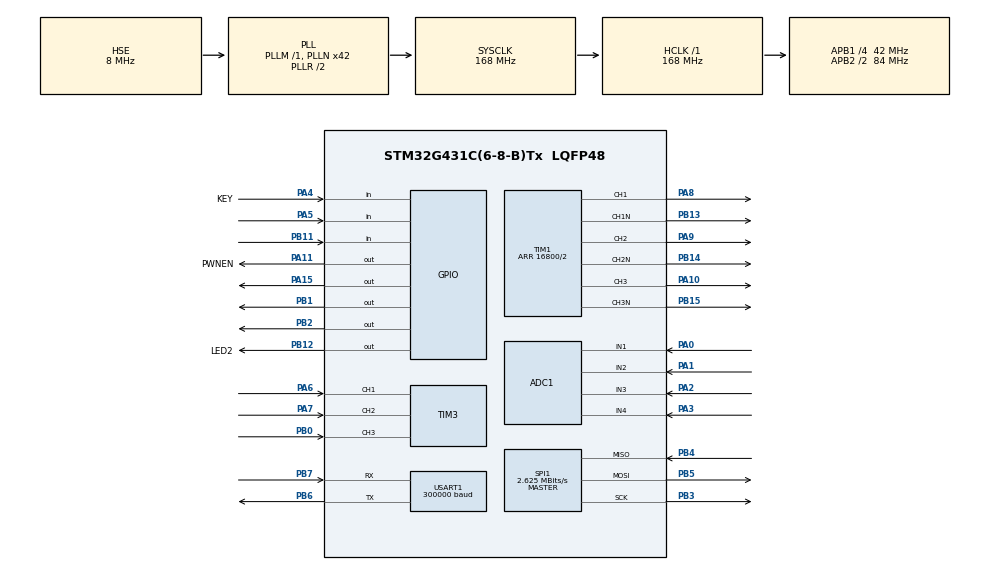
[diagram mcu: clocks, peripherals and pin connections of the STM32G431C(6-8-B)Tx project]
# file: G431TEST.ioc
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ADC1.Channel-10\#ChannelRegularConversion=ADC_CHANNEL_4
ADC1.Channel-7\#ChannelRegularConversion=ADC_CHANNEL_1
ADC1.Channel-8\#ChannelRegularConversion=ADC_CHANNEL_2
ADC1.Channel-9\#ChannelRegularConversion=ADC_CHANNEL_3
ADC1.ClockPrescaler=ADC_CLOCK_SYNC_PCLK_DIV4
ADC1.ContinuousConvMode=ENABLE
ADC1.DMAContinuousRequests=ENABLE
ADC1.EOCSelection=ADC_EOC_SINGLE_CONV
ADC1.EnableInjectedConversion=ENABLE
ADC1.EnableInjectedOversampling=DISABLE
ADC1.EnableRegularConversion=ENABLE
ADC1.ExternalTrigInjecConv=ADC_EXTERNALTRIGINJEC_T1_TRGO
ADC1.ExternalTrigInjecConvEdge=ADC_EXTERNALTRIGINJECCONV_EDGE_RISING
ADC1.InjNumberOfConversion=4
ADC1.InjectedChannel-1\#ChannelInjectedConversion=ADC_CHANNEL_1
ADC1.InjectedChannel-2\#ChannelInjectedConversion=ADC_CHANNEL_2
ADC1.InjectedChannel-5\#ChannelInjectedConversion=ADC_CHANNEL_3
ADC1.InjectedChannel-6\#ChannelInjectedConversion=ADC_CHANNEL_4
ADC1.InjectedConvMode=None
ADC1.InjectedOffsetNumber-1\#ChannelInjectedConversion=ADC_OFFSET_NONE
ADC1.InjectedOffsetNumber-2\#ChannelInjectedConversion=ADC_OFFSET_NONE
ADC1.InjectedOffsetNumber-5\#ChannelInjectedConversion=ADC_OFFSET_NONE
ADC1.InjectedOffsetNumber-6\#ChannelInjectedConversion=ADC_OFFSET_NONE
ADC1.InjectedRank-1\#ChannelInjectedConversion=1
ADC1.InjectedRank-2\#ChannelInjectedConversion=2
ADC1.InjectedRank-5\#ChannelInjectedConversion=3
ADC1.InjectedRank-6\#ChannelInjectedConversion=4
ADC1.InjectedSamplingTime-1\#ChannelInjectedConversion=ADC_SAMPLETIME_12CYCLES_5
ADC1.InjectedSamplingTime-2\#ChannelInjectedConversion=ADC_SAMPLETIME_12CYCLES_5
ADC1.InjectedSamplingTime-5\#ChannelInjectedConversion=ADC_SAMPLETIME_12CYCLES_5
ADC1.InjectedSamplingTime-6\#ChannelInjectedConversion=ADC_SAMPLETIME_12CYCLES_5
ADC1.NbrOfConversion=4
ADC1.NbrOfConversionFlag=1
ADC1.OffsetNumber-10\#ChannelRegularConversion=ADC_OFFSET_NONE
ADC1.OffsetNumber-7\#ChannelRegularConversion=ADC_OFFSET_NONE
ADC1.OffsetNumber-8\#ChannelRegularConversion=ADC_OFFSET_NONE
ADC1.OffsetNumber-9\#ChannelRegularConversion=ADC_OFFSET_NONE
ADC1.Rank-10\#ChannelRegularConversion=4
ADC1.Rank-7\#ChannelRegularConversion=1
ADC1.Rank-8\#ChannelRegularConversion=2
ADC1.Rank-9\#ChannelRegularConversion=3
ADC1.SamplingTime-10\#ChannelRegularConversion=ADC_SAMPLETIME_12CYCLES_5
ADC1.SamplingTime-7\#ChannelRegularConversion=ADC_SAMPLETIME_12CYCLES_5
ADC1.SamplingTime-8\#ChannelRegularConversion=ADC_SAMPLETIME_12CYCLES_5
ADC1.SamplingTime-9\#ChannelRegularConversion=ADC_SAMPLETIME_12CYCLES_5
ADC1.injectedQueueMode=DISABLE
ADC1.master=1
Dma.ADC1.2.Direction=DMA_PERIPH_TO_MEMORY
Dma.ADC1.2.EventEnable=DISABLE
Dma.ADC1.2.Instance=DMA1_Channel1
Dma.ADC1.2.MemDataAlignment=DMA_MDATAALIGN_HALFWORD
Dma.ADC1.2.MemInc=DMA_MINC_ENABLE
Dma.ADC1.2.Mode=DMA_CIRCULAR
Dma.ADC1.2.PeriphDataAlignment=DMA_PDATAALIGN_HALFWORD
Dma.ADC1.2.PeriphInc=DMA_PINC_DISABLE
Dma.ADC1.2.Polarity=HAL_DMAMUX_REQ_GEN_RISING
Dma.ADC1.2.Priority=DMA_PRIORITY_VERY_HIGH
Dma.ADC1.2.RequestNumber=1
Dma.ADC1.2.SignalID=NONE
Dma.ADC1.2.SyncEnable=DISABLE
Dma.ADC1.2.SyncPolarity=HAL_DMAMUX_SYNC_NO_EVENT
Dma.ADC1.2.SyncRequestNumber=1
Dma.ADC1.2.SyncSignalID=NONE
Dma.Request0=USART1_TX
Dma.Request1=USART1_RX
Dma.Request2=ADC1
Dma.USART1_RX.1.Direction=DMA_PERIPH_TO_MEMORY
Dma.USART1_RX.1.EventEnable=DISABLE
Dma.USART1_RX.1.Instance=DMA1_Channel4
Dma.USART1_RX.1.MemDataAlignment=DMA_MDATAALIGN_BYTE
Dma.USART1_RX.1.MemInc=DMA_MINC_ENABLE
Dma.USART1_RX.1.Mode=DMA_CIRCULAR
Dma.USART1_RX.1.PeriphDataAlignment=DMA_PDATAALIGN_BYTE
Dma.USART1_RX.1.PeriphInc=DMA_PINC_DISABLE
Dma.USART1_RX.1.Polarity=HAL_DMAMUX_REQ_GEN_RISING
Dma.USART1_RX.1.Priority=DMA_PRIORITY_VERY_HIGH
Dma.USART1_RX.1.RequestNumber=1
Dma.USART1_RX.1.SignalID=NONE
Dma.USART1_RX.1.SyncEnable=DISABLE
Dma.USART1_RX.1.SyncPolarity=HAL_DMAMUX_SYNC_NO_EVENT
Dma.USART1_RX.1.SyncRequestNumber=1
Dma.USART1_RX.1.SyncSignalID=NONE
Dma.USART1_TX.0.Direction=DMA_MEMORY_TO_PERIPH
Dma.USART1_TX.0.EventEnable=DISABLE
Dma.USART1_TX.0.Instance=DMA1_Channel3
Dma.USART1_TX.0.MemDataAlignment=DMA_MDATAALIGN_BYTE
Dma.USART1_TX.0.MemInc=DMA_MINC_ENABLE
Dma.USART1_TX.0.Mode=DMA_NORMAL
Dma.USART1_TX.0.PeriphDataAlignment=DMA_PDATAALIGN_BYTE
Dma.USART1_TX.0.PeriphInc=DMA_PINC_DISABLE
Dma.USART1_TX.0.Polarity=HAL_DMAMUX_REQ_GEN_RISING
Dma.USART1_TX.0.Priority=DMA_PRIORITY_HIGH
Dma.USART1_TX.0.RequestNumber=1
Dma.USART1_TX.0.SignalID=NONE
Dma.USART1_TX.0.SyncEnable=DISABLE
Dma.USART1_TX.0.SyncPolarity=HAL_DMAMUX_SYNC_NO_EVENT
Dma.USART1_TX.0.SyncRequestNumber=1
Dma.USART1_TX.0.SyncSignalID=NONE
Mcu.Family=STM32G4
Mcu.Name=STM32G431C(6-8-B)Tx
Mcu.Package=LQFP48
NVIC.ADC1_2_IRQn=true\:1\:0\:true\:false\:true\:true\:true
NVIC.DMA1_Channel3_IRQn=true\:0\:0\:true\:false\:true\:true\:true
NVIC.PriorityGroup=NVIC_PRIORITYGROUP_4
NVIC.TIM3_IRQn=true\:2\:0\:true\:false\:true\:true\:true
NVIC.USART1_IRQn=true\:2\:0\:true\:false\:true\:true\:true
PA0.Mode=IN1-Single-Ended
PA0.Signal=ADC1_IN1
PA1.Mode=IN2-Single-Ended
PA1.Signal=ADC1_IN2
PA10.Signal=S_TIM1_CH3
PA11.GPIO_Label=PWNEN
PA11.Signal=GPIO_Output
PA13.Mode=Serial_Wire
PA13.Signal=SYS_JTMS-SWDIO
PA14.Mode=Serial_Wire
PA14.Signal=SYS_JTCK-SWCLK
PA15.Signal=GPIO_Output
PA2.Mode=IN3-Single-Ended
PA2.Signal=ADC1_IN3
PA3.Mode=IN4-Single-Ended
PA3.Signal=ADC1_IN4
PA4.GPIO_Label=KEY
PA4.Signal=GPIO_Input
PA5.Signal=GPIO_Input
PA6.Signal=S_TIM3_CH1
PA7.Signal=S_TIM3_CH2
PA8.Signal=S_TIM1_CH1
PA9.Signal=S_TIM1_CH2
PB0.Signal=S_TIM3_CH3
PB1.Signal=GPIO_Output
PB11.Signal=GPIO_Input
PB12.GPIO_Label=LED2
PB12.PinState=GPIO_PIN_SET
PB12.Signal=GPIO_Output
PB13.Mode=PWM Generation1 CH1 CH1N
PB13.Signal=TIM1_CH1N
PB14.Mode=PWM Generation2 CH2 CH2N
PB14.Signal=TIM1_CH2N
PB15.Mode=PWM Generation3 CH3 CH3N
PB15.Signal=TIM1_CH3N
PB2.Signal=GPIO_Output
PB3.Mode=Full_Duplex_Master
PB3.Signal=SPI1_SCK
PB4.Mode=Full_Duplex_Master
PB4.Signal=SPI1_MISO
PB5.Mode=Full_Duplex_Master
PB5.Signal=SPI1_MOSI
PB6.Mode=Asynchronous
PB6.Signal=USART1_TX
PB7.Mode=Asynchronous
PB7.Signal=USART1_RX
PF0-OSC_IN.Mode=HSE-External-Oscillator
PF0-OSC_IN.Signal=RCC_OSC_IN
PF1-OSC_OUT.Mode=HSE-External-Oscillator
PF1-OSC_OUT.Signal=RCC_OSC_OUT
ProjectManager.HeapSize=0x200
ProjectManager.StackSize=0x400
ProjectManager.TargetToolchain=MDK-ARM V5.32
RCC.ADC12Freq_Value=168000000
RCC.AHBFreq_Value=168000000
RCC.APB1CLKDivider=RCC_HCLK_DIV4
RCC.APB1Freq_Value=42000000
RCC.APB1TimFreq_Value=84000000
RCC.APB2CLKDivider=RCC_HCLK_DIV2
RCC.APB2Freq_Value=84000000
RCC.APB2TimFreq_Value=168000000
RCC.CortexFreq_Value=168000000
RCC.EXTERNAL_CLOCK_VALUE=12288000
RCC.HCLKFreq_Value=168000000
RCC.HSE_VALUE=8000000
RCC.HSI48_VALUE=48000000
RCC.HSI_VALUE=16000000
RCC.LSE_VALUE=32768
RCC.PLLN=42
RCC.PLLSourceVirtual=RCC_PLLSOURCE_HSE
RCC.SYSCLKFreq_VALUE=168000000
RCC.SYSCLKSource=RCC_SYSCLKSOURCE_PLLCLK
RCC.USBFreq_Value=168000000
RCC.VCOOutputFreq_Value=336000000
SH.S_TIM1_CH1.0=TIM1_CH1,PWM Generation1 CH1 CH1N
SH.S_TIM1_CH2.0=TIM1_CH2,PWM Generation2 CH2 CH2N
SH.S_TIM1_CH3.0=TIM1_CH3,PWM Generation3 CH3 CH3N
SH.S_TIM3_CH1.0=TIM3_CH1,Encoder_Interface
SH.S_TIM3_CH2.0=TIM3_CH2,Encoder_Interface
SH.S_TIM3_CH3.0=TIM3_CH3,Input_Capture3_from_TI3
SPI1.BaudRatePrescaler=SPI_BAUDRATEPRESCALER_32
SPI1.CLKPhase=SPI_PHASE_2EDGE
SPI1.CalculateBaudRate=2.625 MBits/s
SPI1.DataSize=SPI_DATASIZE_16BIT
SPI1.Direction=SPI_DIRECTION_2LINES
SPI1.Mode=SPI_MODE_MASTER
SPI1.VirtualType=VM_MASTER
TIM1.AutoReloadPreload=TIM_AUTORELOAD_PRELOAD_ENABLE
TIM1.AutomaticOutput=TIM_AUTOMATICOUTPUT_ENABLE
TIM1.BreakState=TIM_BREAK_DISABLE
TIM1.Channel-PWM\ Generation1\ CH1\ CH1N=TIM_CHANNEL_1
TIM1.Channel-PWM\ Generation2\ CH2\ CH2N=TIM_CHANNEL_2
TIM1.Channel-PWM\ Generation3\ CH3\ CH3N=TIM_CHANNEL_3
TIM1.CounterMode=TIM_COUNTERMODE_CENTERALIGNED1
TIM1.DeadTime=100
TIM1.LockLevel=TIM_LOCKLEVEL_1
TIM1.OCMode_PWM-PWM\ Generation1\ CH1\ CH1N=TIM_OCMODE_PWM2
TIM1.OCMode_PWM-PWM\ Generation2\ CH2\ CH2N=TIM_OCMODE_PWM2
TIM1.OCMode_PWM-PWM\ Generation3\ CH3\ CH3N=TIM_OCMODE_PWM2
TIM1.OCPolarity_1=TIM_OCPOLARITY_HIGH
TIM1.OCPolarity_2=TIM_OCPOLARITY_HIGH
TIM1.OCPolarity_3=TIM_OCPOLARITY_HIGH
TIM1.OffStateIDLEMode=TIM_OSSI_ENABLE
TIM1.OffStateRunMode=TIM_OSSR_ENABLE
TIM1.PeriodNoDither=16800/2
TIM1.PulseNoDither_1=4200
TIM1.PulseNoDither_2=4200
TIM1.PulseNoDither_3=4200
TIM1.RepetitionCounter=1
TIM1.TIM_MasterOutputTrigger=TIM_TRGO_UPDATE
TIM3.Channel-Input_Capture3_from_TI3=TIM_CHANNEL_3
TIM3.ICPrescaler-Input_Capture3_from_TI3=TIM_ICPSC_DIV2
USART1.BaudRate=300000
USART1.VirtualMode-Asynchronous=VM_ASYNC
VP_SYS_VS_DBSignals.Mode=DisableDeadBatterySignals
VP_TIM1_VS_ClockSourceINT.Mode=Internal
board=custom

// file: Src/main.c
/* USER CODE BEGIN Header */
/**
  ******************************************************************************
  * @file           : main.c
  * @brief          : Main program body
  ******************************************************************************
  * @attention
  *
  * <h2><center>&copy; Copyright (c) 2023 STMicroelectronics.
  * All rights reserved.</center></h2>
  *
  * This software component is licensed by ST under BSD 3-Clause license,
  * the "License"; You may not use this file except in compliance with the
  * License. You may obtain a copy of the License at:
  *                        opensource.org/licenses/BSD-3-Clause
  *
  ******************************************************************************
  */
/* USER CODE END Header */
#include "main.h"
#include "adc.h"
#include "dma.h"
#include "spi.h"
#include "tim.h"
#include "usart.h"
#include "gpio.h"

/* USER CODE BEGIN Includes */
#include "user.h"
#include "flash.h"
/* USER CODE END Includes */

void SystemClock_Config(void);

int main(void)
{

  /* MCU Configuration--------------------------------------------------------*/

  /* Reset of all peripherals, Initializes the Flash interface and the Systick. */
  HAL_Init();

  /* Configure the system clock */
  SystemClock_Config();

  /* Initialize all configured peripherals */
  MX_GPIO_Init();
  MX_DMA_Init();
  MX_ADC1_Init();
  MX_TIM1_Init();
  MX_TIM3_Init();
  MX_USART1_UART_Init();
  MX_SPI1_Init();
  /* USER CODE BEGIN 2 */
	SysInit();  //初始化，需要手动完成
  /* USER CODE END 2 */

  /* Infinite loop */
  while (1)
  {

    /* USER CODE BEGIN 3 */
		MainLoop(); //普通任务主循环
  }
  /* USER CODE END 3 */
}

void SystemClock_Config(void)
{
  RCC_OscInitTypeDef RCC_OscInitStruct = {0};
  RCC_ClkInitTypeDef RCC_ClkInitStruct = {0};
  RCC_PeriphCLKInitTypeDef PeriphClkInit = {0};

  /** Configure the main internal regulator output voltage
  */
  HAL_PWREx_ControlVoltageScaling(PWR_REGULATOR_VOLTAGE_SCALE1_BOOST);
  /** Initializes the RCC Oscillators according to the specified parameters
  * in the RCC_OscInitTypeDef structure.
  */
  RCC_OscInitStruct.OscillatorType = RCC_OSCILLATORTYPE_HSE;
  RCC_OscInitStruct.HSEState = RCC_HSE_ON;
  RCC_OscInitStruct.PLL.PLLState = RCC_PLL_ON;
  RCC_OscInitStruct.PLL.PLLSource = RCC_PLLSOURCE_HSE;
  RCC_OscInitStruct.PLL.PLLM = RCC_PLLM_DIV1;
  RCC_OscInitStruct.PLL.PLLN = 42;
  RCC_OscInitStruct.PLL.PLLP = RCC_PLLP_DIV2;
  RCC_OscInitStruct.PLL.PLLQ = RCC_PLLQ_DIV2;
  RCC_OscInitStruct.PLL.PLLR = RCC_PLLR_DIV2;
  if (HAL_RCC_OscConfig(&RCC_OscInitStruct) != HAL_OK)
  {
    Error_Handler();
  }
  /** Initializes the CPU, AHB and APB buses clocks
  */
  RCC_ClkInitStruct.ClockType = RCC_CLOCKTYPE_HCLK|RCC_CLOCKTYPE_SYSCLK
                              |RCC_CLOCKTYPE_PCLK1|RCC_CLOCKTYPE_PCLK2;
  RCC_ClkInitStruct.SYSCLKSource = RCC_SYSCLKSOURCE_PLLCLK;
  RCC_ClkInitStruct.AHBCLKDivider = RCC_SYSCLK_DIV1;
  RCC_ClkInitStruct.APB1CLKDivider = RCC_HCLK_DIV4;
  RCC_ClkInitStruct.APB2CLKDivider = RCC_HCLK_DIV2;

  if (HAL_RCC_ClockConfig(&RCC_ClkInitStruct, FLASH_LATENCY_4) != HAL_OK)
  {
    Error_Handler();
  }
  /** Initializes the peripherals clocks
  */
  PeriphClkInit.PeriphClockSelection = RCC_PERIPHCLK_USART1|RCC_PERIPHCLK_ADC12;
  PeriphClkInit.Usart1ClockSelection = RCC_USART1CLKSOURCE_PCLK2;
  PeriphClkInit.Adc12ClockSelection = RCC_ADC12CLKSOURCE_SYSCLK;
  if (HAL_RCCEx_PeriphCLKConfig(&PeriphClkInit) != HAL_OK)
  {
    Error_Handler();
  }
}

void Error_Handler(void)
{
  __disable_irq();
  while (1)
  {
  }
}

/************************ (C) COPYRIGHT STMicroelectronics *****END OF FILE****/
